# Polarfire SoC register map
Vendor: Microchip; File version: 1.0
CPU: Microchip PolarFire SoC 1.0, little endian
Registers are 32-bit, read-write, reset 0x0 unless marked. A register's access mark holds for its fields unless they carry their own. Offsets are from the block's base; [hi:lo] are bit positions.

## GEM_A_LO (part 3 of 8) — GEM_A_LO Controller
Base 0x20110000
Same registers: GEM_B_LO 0x20112000, GEM_A_HI 0x28110000, GEM_B_HI 0x28112000
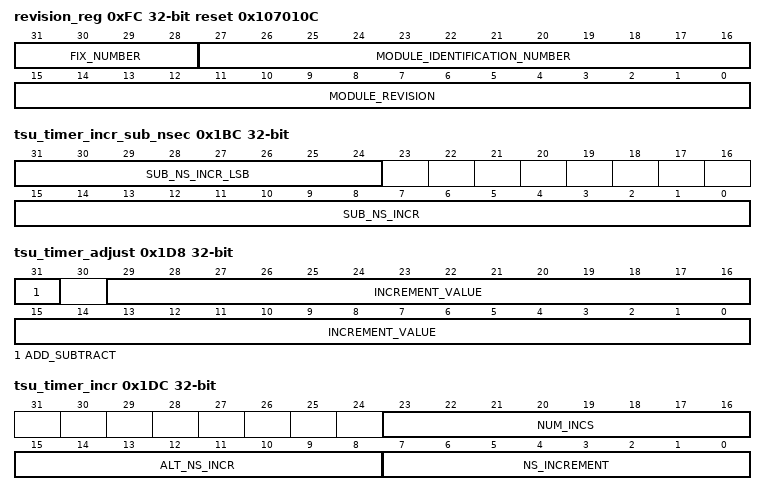
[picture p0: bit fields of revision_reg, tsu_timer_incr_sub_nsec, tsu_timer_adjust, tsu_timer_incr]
0xFC revision_reg ro reset 0x107010C — This register indicates a Cadence module identification number and module revision. The value of this register is read only as defined by 'gem_revision_reg_value
  [31:28] FIX_NUMBER — Fix number - incremented for fix releases.
  [27:16] MODULE_IDENTIFICATION_NUMBER — Module identification number - for the GEM, this value is fixed.
  [15:0] MODULE_REVISION — Module revision - fixed value specific to the revision of the design which is incremented for each non-fix release of the IP.
0x100 octets_txed_bottom ro — These registers reset to zero on a read and stick at all ones when they count to their maximum value. They should be read frequently enough to prevent loss of data. In order to reduce overall design area, the statistics registers may be optionally removed in the configuration file if they are deemed unnecessary for a particular design. The receive statistics registers are only incremented when the receive enable bit is set in the network control register. The statistics registers optionally have a snapshot capability which, when exercised, will simultaneously store and clear the current values of all the statistics registers into a snapshot register set in order to allow a consistent set of statistics to be read by the processor. The snapshot is controlled using bit 13 of the network control register. The read snapshot control indicated by bit 14 of the network control register determines whether the processor reads the snapshot registers (logic 1) or the incrementing registers (logic 0). The default GEM configuration does not support the snapshot capability. See Parameterization section under Implementation Application Notes for an explanation of how to enable this function. All the statistics registers are read only. For test purposes they may be written by setting bit 7 (Write Enable) in the network control register. Setting bit 6 (increment statistics) in the network control register causes all the statistics registers to increment by one, again for test purposes. Once a statistics register has been read, it is automatically cleared. When reading the octets transmitted and octets received registers, bits 31:0 should be read prior to bits 47:32 to ensure reliable operation. The statistics register block contains the following registers. Octets Transmitted [31:0]
  [31:0] COUNT rw — Transmitted octets in frame without errors [31:0]. The number of octets transmitted in valid frames of any type. This counter is 48-bits, and is read through two registers. This count does not include octets from automatically generated pause frames.
0x104 octets_txed_top ro — Octets Transmitted 47:32
  [15:0] COUNT rw — Transmitted octets in frame without errors [47:32]. The number of octets transmitted in valid frames of any type. This counter is 48-bits, and is read through two registers. This count does not include octets from automatically generated pause frames.
0x108 frames_txed_ok ro — Frames Transmitted
  [31:0] COUNT rw — Frames transmitted without error. A 32 bit register counting the number of frames successfully transmitted, i.e. no under run and not too many retries. Excludes pause frames.
0x10C broadcast_txed ro — Broadcast Frames Transmitted
  [31:0] COUNT rw — Broadcast frames transmitted without error. A 32 bit register counting the number of broadcast frames successfully transmitted without error, i.e. no under run and not too many retries. Excludes pause frames.
0x110 multicast_txed ro — Multicast Frames Transmitted
  [31:0] COUNT rw — Multicast frames transmitted without error. A 32 bit register counting the number of multicast frames successfully transmitted without error, i.e. no under run and not too many retries. Excludes pause frames.
0x114 pause_frames_txed ro — Pause Frames Transmitted
  [15:0] COUNT rw — Transmitted pause frames - a 16 bit register counting the number of pause frames transmitted. Only pause frames triggered by the register interface or through the external pause pins or automatically when rx_water_mark is reached are counted as pause frames. Pause frames received through the external FIFO interface are counted in the frames transmitted counter.
0x118 frames_txed_64 ro — 64 Byte Frames Transmitted
  [31:0] COUNT rw — 64 byte frames transmitted without error. A 32 bit register counting the number of 64 byte frames successfully transmitted without error, i.e. no under run and not too many retries. Excludes pause frames.
0x11C frames_txed_65 ro — 65 to 127 Byte Frames Transmitted
  [31:0] COUNT rw — 65 to127 byte frames transmitted without error. A 32 bit register counting the number of 65 to127 byte frames successfully transmitted without error, i.e. no under run and not too many retries.
0x120 frames_txed_128 ro — 128 to 255 Byte Frames Transmitted
  [31:0] COUNT rw — 128 to 255 byte frames transmitted without error. A 32 bit register counting the number of 128 to 255 byte frames successfully transmitted without error, i.e. no under run and not too many retries.
0x124 frames_txed_256 ro — 256 to 511 Byte Frames Transmitted
  [31:0] COUNT rw — 256 to 511 byte frames transmitted without error. A 32 bit register counting the number of 256 to 511 byte frames successfully transmitted without error, i.e. no under run and not too many retries.
0x128 frames_txed_512 ro — 512 to 1023 Byte Frames Transmitted
  [31:0] COUNT rw — 512 to 1023 byte frames transmitted without error. A 32 bit register counting the number of 512 to 1023 byte frames successfully transmitted without error, i.e. no under run and not too many retries.
0x12C frames_txed_1024 ro — 1024 to 1518 Byte Frames Transmitted
  [31:0] COUNT rw — 1024 to 1518 byte frames transmitted without error. A 32 bit register counting the number of 1024 to 1518 byte frames successfully transmitted without error, i.e. no under run and not too many retries.
0x130 frames_txed_1519 ro — Greater Than 1518 Byte Frames Transmitted
  [31:0] COUNT rw — Greater than 1518 byte frames transmitted without error. A 32 bit register counting the number of 1518 or above byte frames successfully transmitted without error, i.e. no under run and not too many retries.
0x134 tx_underruns ro — Transmit Under Runs
  [9:0] COUNT rw — Transmit under runs - a 10 bit register counting the number of frames not transmitted due to a transmit under run. If this register is incremented then no other statistics register is incremented.
0x138 single_collisions ro — Single Collision Frames
  [17:0] COUNT rw — Single collision frames - an 18 bit register counting the number of frames experiencing a single collision before being successfully transmitted, i.e. no under run.
0x13C multiple_collisions ro — Multiple Collision Frames
  [17:0] COUNT rw — Multiple collision frames - an 18 bit register counting the number of frames experiencing between two and fifteen collisions prior to being successfully transmitted, i.e. no under run and not too many retries.
0x140 excessive_collisions ro
  [9:0] COUNT rw — Excessive collisions - a 10 bit register counting the number of frames that failed to be transmitted because they experienced 16 collisions.
0x144 late_collisions ro
  [9:0] COUNT rw — Late collisions - a 10 bit register counting the number of late collision occurring after the slot time (512 bits) has expired. In 10/100 mode, late collisions are counted twice i.e. both as a collision and a late collision. In gigabit mode, a late collision causes the transmission to be aborted, thus the single and multi collision registers are not updated.
0x148 deferred_frames ro — Deferred Transmission Frames
  [17:0] COUNT rw — Deferred transmission frames - an 18 bit register counting the number of frames experiencing deferral due to carrier sense being active on their first attempt at transmission. Frames involved in any collision are not counted nor are frames that experienced a transmit under run.
0x14C crs_errors ro — Carrier Sense Errors
  [9:0] COUNT rw — Carrier sense errors - a 10 bit register counting the number of frames transmitted where carrier sense was not seen during transmission or where carrier sense was deasserted after being asserted in a transmit frame without collision (no under run). Only incremented in half-duplex mode. The only effect of a carrier sense error is to increment this register. The behaviour of the other statistics registers is unaffected by the detection of a carrier sense error.
0x150 octets_rxed_bottom ro — Octets Received 31:0
  [31:0] COUNT rw — Received octets in frame without errors [31:0]. The number of octets received in valid frames of any type. This counter is 48-bits and is read through two registers. This count does not include octets from pause frames, and is only incremented if the frame is successfully filtered.
0x154 octets_rxed_top ro — Octets Received 47:32
  [15:0] COUNT rw — Received octets in frame without errors [47:32]. The number of octets received in valid frames of any type. This counter is 48-bits and is read through two registers. This count does not include octets from pause frames, and is only incremented if the frame is successfully filtered.
0x158 frames_rxed_ok ro — Frames Received
  [31:0] COUNT rw — Frames received without error. A 32 bit register counting the number of frames successfully received. Excludes pause frames, and is only incremented if the frame is successfully filtered.
0x15C broadcast_rxed ro — Broadcast Frames Received
  [31:0] COUNT rw — Broadcast frames received without error. A 32 bit register counting the number of broadcast frames successfully received without error. Excludes pause frames, and is only incremented if the frame is successfully filtered.
0x160 multicast_rxed ro — Multicast Frames Received
  [31:0] COUNT rw — Multicast frames received without error. A 32 bit register counting the number of multicast frames successfully received without error. Excludes pause frames, and is only incremented if the frame is successfully filtered.
0x164 pause_frames_rxed ro — Pause Frames Received
  [15:0] COUNT rw — Received pause frames - a 16 bit register counting the number of pause frames received without error.
0x168 frames_rxed_64 ro — 64 Byte Frames Received
  [31:0] COUNT rw — 64 byte frames received without error. A 32 bit register counting the number of 64 byte frames successfully received without error. Excludes pause frames, and is only incremented if the frame is successfully filtered.
0x16C frames_rxed_65 ro — 65 to 127 Byte Frames Received
  [31:0] COUNT rw — 65 to 127 byte frames received without error. A 32 bit register counting the number of 65 to 127 byte frames successfully received without error. Excludes pause frames, and is only incremented if the frame is successfully filtered.
0x170 frames_rxed_128 ro — 128 to 255 Byte Frames Received
  [31:0] COUNT rw — 128 to 255 byte frames received without error. A 32 bit register counting the number of 128 to 255 byte frames successfully received without error. Excludes pause frames, and is only incremented if the frame is successfully filtered.
0x174 frames_rxed_256 ro — 256 to 511 Byte Frames Received
  [31:0] COUNT rw — 256 to 511 byte frames received without error. A 32 bit register counting the number of 256 to 511 byte frames successfully transmitted without error. Excludes pause frames, and is only incremented if the frame is successfully filtered.
0x178 frames_rxed_512 ro — 512 to 1023 Byte Frames Received
  [31:0] COUNT rw — 512 to 1023 byte frames received without error. A 32 bit register counting the number of 512 to 1023 byte frames successfully received without error. Excludes pause frames, and is only incremented if the frame is successfully filtered.
0x17C frames_rxed_1024 ro — 1024 to 1518 Byte Frames Received
  [31:0] COUNT rw — 1024 to 1518 byte frames received without error. A 32 bit register counting the number of 1024 to 1518 byte frames successfully received without error. Excludes pause frames, and is only incremented if the frame is successfully filtered.
0x180 frames_rxed_1519 ro — 1519 to maximum Byte Frames Received
  [31:0] COUNT rw — 1519 to maximum byte frames received without error. A 32 bit register counting the number of 1519 byte or above frames successfully received without error. Maximum frame size is determined by the network configuration register bit 8 (1536 maximum frame size) or bit 3 (jumbo frame size). Excludes pause frames, and is only incremented if the frame is successfully filtered.
0x184 undersize_frames ro — Undersized Frames Received
  [9:0] COUNT rw — Undersize frames received - a 10 bit register counting the number of frames received less than 64 bytes in length (10/100 mode or gigabit mode, full duplex) that do not have either a CRC error or an alignment error. In gigabit mode, half-duplex, this register counts either frames not conforming to the minimum slot time of 512 bytes or frames not conforming to the minimum frame size once bursting is active.
0x188 excessive_rx_length ro — Oversize Frames Received
  [9:0] COUNT rw — Oversize frames received - a 10 bit register counting the number of frames received exceeding 1518 bytes (1536 bytes if bit 8 is set in network configuration register, 10,240 bytes if bit 3 is set in the network configuration register) in length but do not have either a CRC error, an alignment error nor a receive symbol error.
0x18C rx_jabbers ro — Jabbers Received
  [9:0] COUNT rw — Jabbers received - a 10 bit register counting the number of frames received exceeding 1518 bytes (1536 if bit 8 set in network configuration register, 10,240 bytes if bit 3 is set in the network configuration register) in length and have either a CRC error, an alignment error or a receive symbol error.
0x190 fcs_errors ro — Frame Check Sequence Errors
  [9:0] COUNT rw — Frame check sequence errors - a 10 bit register counting frames that are an integral number of bytes, have bad CRC and are between 64 and 1518 bytes in length (1536 if bit 8 set in network configuration register, 10,240 bytes if bit 3 is set in the network configuration register). This register is also incremented if a symbol error is detected and the frame is of valid length and has an integral number of bytes. This register is incremented for a frame with bad FCS, regardless of whether it is copied to memory due to ignore FCS mode being enabled in bit 26 of the network configuration register.
0x194 rx_length_errors ro — Length Field Frame Errors
  [9:0] COUNT rw — Length field frame errors - this 10-bit register counts the number of frames received that have a measured length shorter than that extracted from the length field (bytes 13 and 14). This condition is only counted if the value of the length field is less than 0x0600, the frame is not of excessive length and checking is enabled through bit 16 of the network configuration register.
0x198 rx_symbol_errors ro — Receive Symbol Errors
  [9:0] COUNT rw — Receive symbol errors - a 10-bit register counting the number of frames that had rx_er asserted during reception. For 10/100 mode symbol errors are counted regardless of frame length checks. For gigabit mode the frame must satisfy slot time requirements in order to count a symbol error. Additionally, in gigabit half-duplex mode, carrier extension errors are also recorded. Receive symbol errors will also be counted as an FCS or alignment error if the frame is between 64 and 1518 bytes (1536 bytes if bit 8 is set in the network configuration register, 10240 bytes if bit 3 is set in the network configuration register). If the frame is larger it will be recorded as a jabber error.
0x19C alignment_errors ro
  [9:0] COUNT rw — Alignment errors - a 10 bit register counting frames that are not an integral number of bytes long and have bad CRC when their length is truncated to an integral number of bytes and are between 64 and 1518 bytes in length (1536 if bit 8 set in network configuration register, 10,240 bytes if bit 3 is set in the network configuration register). This register is also incremented if a symbol error is detected and the frame is of valid length and does not have an integral number of bytes.
0x1A0 rx_resource_errors ro — Receive Resource Errors
  [17:0] COUNT rw — Receive resource errors - an 18 bit register counting the number of times a receive buffer descriptor was read with its used bit set. This can be used as a means of checking the efficiency of the software in processing and releasing receive buffers. In an ideally configured system, this counter would not increase.
0x1A4 rx_overruns ro — Receive Overruns
  [9:0] COUNT rw — Receive overruns - a 10 bit register counting the number of frames that are address recognized but were not copied to memory due to a receive overrun.
0x1A8 rx_ip_ck_errors ro — IP Header Checksum Errors
  [7:0] COUNT rw — IP header checksum errors - an 8-bit register counting the number of frames discarded due to an incorrect IP header checksum, but are between 64 and 1518 bytes (1536 bytes if bit 8 is set in the network configuration register or 10240 bytes if bit 3 is in the network configuration register) and do not have a CRC error, an alignment error, nor a symbol error.
0x1AC rx_tcp_ck_errors ro — TCP Checksum Errors
  [7:0] COUNT rw — TCP checksum errors - an 8-bit register counting the number of frames discarded due to an incorrect TCP checksum, but are between 64 and 1518 bytes (1536 bytes if bit 8 is set in the network configuration register or 10240 bytes if bit 3 is in the network configuration register) and do not have a CRC error, an alignment error, nor a symbol error.
0x1B0 rx_udp_ck_errors ro — UDP Checksum Errors
  [7:0] COUNT rw — UDP checksum errors - an 8-bit register counting the number of frames discarded due to an incorrect UDP checksum, but are between 64 and 1518 bytes (1536 bytes if bit 8 is set in the network configuration register or 10240 bytes if bit 3 is in the network configuration register) and do not have a CRC error, an alignment error, nor a symbol error.
0x1B4 auto_flushed_pkts ro — Receive DMA Flushed Packets
  [15:0] COUNT rw — Flushed RX packets counter. A 16 bit register counting the number of frames that have been flushed from the receive SRAM based packet buffer due to one of the following reasons:, :1. When either partial store and forward mode, bit 24 of the DMA configuration register, or the drop_on_resource_err mode of the traffic policing feature is active, and a packet is received while there is no AMBA (AHB/AXI) resource (no free descriptors for the DUT to use)., :2. When partial store and forward mode is enabled and an AMBA (AHB/AXI) error is encountered while writing the packet data to external memory., :3. When bit 18 of the network control register (software action to flush a packet from the head of the PBUF queue) is pulsed and the GEM DMA is not currently busy., :4. When a frame is dropped due to the policing actions defined in the rx_qX_flush registers located at 0x0b00-0x0b3c.
0x1BC tsu_timer_incr_sub_nsec — 1588 Timer Increment Register sub nsec. From release 1p08f1 onwards this register must be written before the tsu_timer_incr register and the value written will not take effect until the tsu_timer_incr register is written to.
  [31:24] SUB_NS_INCR_LSB — These are the least significant bits [7:0] of the sub-ns value by which the 1588 timer will be incremented each clock cycle.
  [15:0] SUB_NS_INCR — These are the most significant bits [23:8] of the sub-ns value by which the 1588 timer will be incremented each clock cycle. 24 bits of sub nanosecond precision gives resolution of approximately 5.86E-17 seconds (16 bits gives 15.2 femtoseconds).
0x1C0 tsu_timer_msb_sec — 1588 Timer Seconds Register 47:32
  [15:0] TIMER — TSU timer value (s). Most significant 16 bits of seconds timer count. The register is writeable. The 48-bit counter increments by one when the 1588 nanoseconds counter counts to one second. It may also be incremented or decremented when the timer adjust register is written (if decremented from zero the 48-bit combined count would roll back to 0xFFFFFFFFFFFF). Note: The value of this register is used only when the lower 32 bit register is written to. This is to ensure a single update of the 48 bit seconds value
0x1C4 tsu_strobe_msb_sec ro — 1588 Timer Sync Strobe Seconds Register 47:32
  [15:0] STROBE — 1588 Timer Sync Strobe Seconds. The most significant 16-bit value of the Timer Seconds register captured when gem_tsu_ms and gem_tsu_inc_ctrl are zero.
0x1C8 tsu_strobe_sec ro — 1588 Timer Sync Strobe Seconds Register 31:0
  [31:0] STROBE — 1588 Timer Sync Strobe Seconds. The lowest significant 32-bit value of the Timer Seconds register captured when gem_tsu_ms and gem_tsu_inc_ctrl are zero.
0x1CC tsu_strobe_nsec ro — 1588 Timer Sync Strobe Nanoseconds Register
  [29:0] STROBE — 1588 Timer Sync Strobe Nanoseconds. The value of the Timer Nanoseconds register captured when gem_tsu_ms and gem_tsu_inc_ctrl are zero.
0x1D0 tsu_timer_sec — 1588 Timer Seconds Register 31:0
  [31:0] TIMER — 1588 Timer Seconds Register. TSU timer value (s). Least significant 32 bits of seconds timer count. This register is writeable. The 48-bit counter increments by one when the 1588 nanoseconds counter counts to one second. It may also be incremented or decremented when the timer adjust register is written (if decremented from zero the 48-bit combined count would roll back to 0xFFFFFFFFFFFF).
0x1D4 tsu_timer_nsec — 1588 Timer Nanoseconds Register
  [29:0] TIMER — Timer count in nanoseconds. This register is writeable. It can also be adjusted by writes to the 1588 timer adjust register. It increments by the value of the 1588 timer increment register each clock cycle (if this register is close to zero and a write to the timer adjust register causes a decrement the seconds register will be decremented if necessary and the nanoseconds register will roll back to 9999999xx (decimal)).
0x1D8 tsu_timer_adjust — This register is used to adjust the value of the timer in the TSU. It allows an integral number of nanoseconds to be added or subtracted from the timer in a one-off operation. This register returns all zeroes when read.
  [31] ADD_SUBTRACT — Write as one to subtract from the 1588 timer. Write as zero to add to it.
  [29:0] INCREMENT_VALUE — Timer increment value. The number of nanoseconds to increment or decrement the 1588 timer nanoseconds register. If necessary the 1588 seconds register will be incremented or decremented.
0x1DC tsu_timer_incr — 1588 Timer Increment Register. From release 1p08f1 onwards this register must be written after the tsu_timer_incr_sub_ns register and the write operation will cause the value written to the tsu_timer_incr_sub_ns register to take effect.
  [23:16] NUM_INCS — Number of incs before alt inc. The number of increments after which the alternative increment is used.
  [15:8] ALT_NS_INCR — Alternative nanoseconds count. Alternative count of nanoseconds by which the 1588 timer nanoseconds register will be incremented each clock cycle.
  [7:0] NS_INCREMENT — A count of nanoseconds by which the 1588 timer nanoseconds register will be incremented each clock cycle. These are the most significant 8 bits of the 32 bit timer_increment counter. The tsu_timer_incr_sub_nsec register holds the least significant 24 bits of the increment.
0x1E0 tsu_ptp_tx_sec ro — PTP Event Frame Transmitted Seconds Register 31:0
  [31:0] TIMER — PTP Event Frame Transmitted Seconds. The register is updated with the value that the 1588 timer seconds register held when the SFD of a PTP transmit primary event crosses the MII interface. The actual update occurs when the GEM recognizes the frame as a PTP sync or delay_req frame. An interrupt is issued when the register is updated.
0x1E4 tsu_ptp_tx_nsec ro — PTP Event Frame Transmitted Nanoseconds Register
  [29:0] TIMER — PTP Event Frame Transmitted Nanoseconds. The register is updated with the value that the 1588 timer nanoseconds register held when the SFD of a PTP transmit primary event crosses the MII interface. The actual update occurs when the GEM recognizes the frame as a PTP sync or delay_req frame. An interrupt is issued when the register is updated.
0x1E8 tsu_ptp_rx_sec ro — PTP Event Frame Received Seconds Register 31:0
  [31:0] TIMER — PTP Event Frame Received Seconds. The register is updated with the value that the 1588 timer seconds register held when the SFD of a PTP receive primary event crosses the MII interface. The actual update occurs when the GEM recognizes the frame as a PTP sync or delay_req frame. An interrupt is issued when the register is updated.
0x1EC tsu_ptp_rx_nsec ro — PTP Event Frame Received Nanoseconds Register
  [29:0] TIMER — PTP Event Frame Received Nanoseconds. The register is updated with the value that the 1588 timer nanoseconds register held when the SFD of a PTP receive primary event crosses the MII interface. The actual update occurs when the GEM recognizes the frame as a PTP sync or delay_req frame. An interrupt is issued when the register is updated.
0x1F0 tsu_peer_tx_sec ro — PTP Peer Event Frame Transmitted Seconds Register 31:0
  [31:0] TIMER — PTP Peer Event Frame Received Seconds. The register is updated with the value that the 1588 timer seconds register held when the SFD of a PTP transmit peer event crosses the MII interface. The actual update occurs when the GEM recognizes the frame as a PTP pdelay_req or pdelay_resp frame. An interrupt is issued when the register is updated.
0x1F4 tsu_peer_tx_nsec ro — PTP Peer Event Frame Transmitted Nanoseconds Register
  [29:0] TIMER — PTP Peer Event Frame Transmitted Nanoseconds. The register is updated with the value that the 1588 timer nanoseconds register held when the SFD of a PTP transmit peer event crosses the MII interface. The actual update occurs when the GEM recognizes the frame as a PTP pdelay_req or pdelay_resp frame. An interrupt is issued when the register is updated.
0x1F8 tsu_peer_rx_sec ro — PTP Peer Event Frame Received Seconds Register 31:0
  [31:0] TIMER — PTP Peer Event Frame Received Seconds. The register is updated with the value that the 1588 timer seconds register held when the SFD of a PTP receive peer event crosses the MII interface. The actual update occurs when the GEM recognizes the frame as a PTP pdelay_req or pdelay_resp frame. An interrupt is issued when the register is updated.
0x1FC tsu_peer_rx_nsec ro — PTP Peer Event Frame Received Nanoseconds Register
  [29:0] TIMER — PTP Peer Event Frame Received Nanoseconds. The register is updated with the value that the 1588 timer nanoseconds register held when the SFD of a PTP receive peer event crosses the MII interface. The actual update occurs when the GEM recognizes the frame as a PTP pdelay_req or pdelay_resp frame. An interrupt is issued when the register is updated.
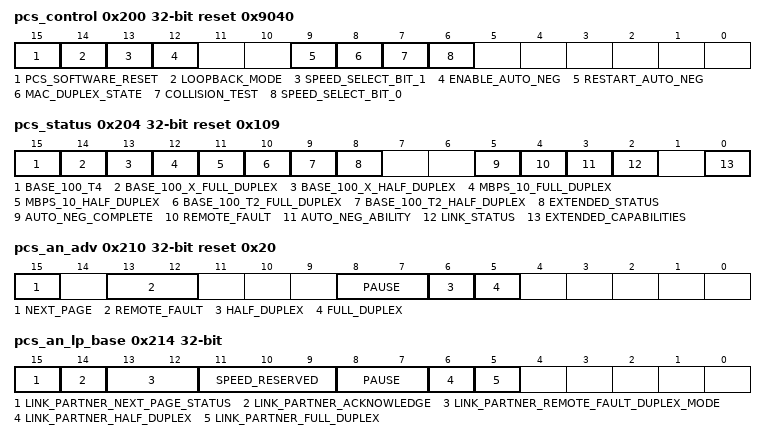
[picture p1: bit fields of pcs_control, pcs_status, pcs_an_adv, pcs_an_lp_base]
0x200 pcs_control reset 0x9040 — Note: All PCS registers are defined in the IEEE 802.3 Standard. PCS Control Register. This register provides the main control functions with respect to the PCS.
  [15] PCS_SOFTWARE_RESET — PCS software reset - written by software to force the hardware logic into a reset state. This bit is self-clearing. When reading this bit, logic 1 is returned until both the soft reset has completed and the PCS is enabled through the PCS select bit of the network configuration register. Writing logic 0 has no effect.
  [14] LOOPBACK_MODE — Loopback mode - the ewrap output pin of the GEM reflects this control bit, and can be used to select loopback mode in the PHY transceiver. 0: Loopback mode disabled. 1: Loopback mode enabled.
  [13] SPEED_SELECT_BIT_1 ro — Speed select bit 1 - combined with speed select [0] to indicate the speed of operation of the PCS. As the GEM PCS is only intended to operate at 1000 Mbps, this bit is hardwired to logic 0.
  [12] ENABLE_AUTO_NEG — Enable auto-negotiation - when set active high, auto-negotiation operation is enabled.
  [9] RESTART_AUTO_NEG — Restart auto-negotiation - when set active high, the hardware restarts auto-negotiation. This bit is self-clearing, but once set shall remain in this state until auto-negotiation has restarted. Writing logic 0 has no effect.
  [8] MAC_DUPLEX_STATE ro — MAC Duplex state. This returns the value of the MAC's duplex state as indicated in bit 1 of the MAC's network configuration register.
  [7] COLLISION_TEST — Collision test - when set active high, the PCS generates collisions on transmit. This bit should only be set for test purposes.
  [6] SPEED_SELECT_BIT_0 ro — Speed select bit 0 - combined with speed select [1] to indicate the speed of operation of the PCS. As the GEM PCS is only intended to operate at 1000 Mbps, this bit is hardwired to logic 1.
0x204 pcs_status ro reset 0x109 — This register indicates general status information concerning the PCS.
  [15] BASE_100_T4 — 100 BASE-T4 - the GEM PCS does not support 100 BASE-T4. This bit is hardwired to logic 0.
  [14] BASE_100_X_FULL_DUPLEX — 100 BASE-X full duplex - the GEM PCS does not support 100 BASE-X. This bit is hardwired to logic 0.
  [13] BASE_100_X_HALF_DUPLEX — 100 BASE-X half-duplex - the GEM PCS does not support 100 BASE-X. This bit is hardwired to logic 0.
  [12] MBPS_10_FULL_DUPLEX — 10 Mbps full duplex - the GEM PCS does not support this mode. This bit is hardwired to logic 0.
  [11] MBPS_10_HALF_DUPLEX — 10 Mbps half-duplex - the GEM PCS does not support this mode. This bit is hardwired to logic 0.
  [10] BASE_100_T2_FULL_DUPLEX — 100 BASE-T2 full duplex - the GEM PCS does not support 100 BASE-T2. This bit is hardwired to logic 0.
  [9] BASE_100_T2_HALF_DUPLEX — 100 BASE-T2 half-duplex - the GEM PCS does not support 100 BASE-T2. This bit is hardwired to logic 0.
  [8] EXTENDED_STATUS — Extended status - when set active high, indicates extended status information is present in the PCS auto-negotiation extended status register. This bit is hardwired to logic 1.
  [5] AUTO_NEG_COMPLETE — Auto-negotiation complete - set active high by the PCS hardware to indicate auto-negotiation has completed.
  [4] REMOTE_FAULT — Remote fault - set active high if the link partner remote fault bits in the PCS auto-negotiation link partner ability register, indicates an error. Resets low when read.
  [3] AUTO_NEG_ABILITY — Auto-negotiation ability - this bit indicates whether the PCS has auto-negotiation ability and reflects the value of the auto-negotiation enable bit in the PCS control register. 0: PCS is not able to perform auto-negotiation. 1: PCS is able to perform auto-negotiation.
  [2] LINK_STATUS — Link status - indicates the status of the physical connection to the link partner. When set to logic 1 the link is up, and when set to logic 0, the link is down. If auto-negotiation is disabled this returns the synchronisation status. Held at logic 0 if the link goes down until this bit is read.
  [0] EXTENDED_CAPABILITIES — Extended register capabilities - when set active high, indicates the PCS supports extended register capabilities. This bit is hardwired to logic 1.
0x208 pcs_phy_top_id ro reset 0x107 — The value of this register indicates the upper 16-bits of the PHY's identification code. This is a read-only register with a value defined by 'gem_phy_id_top
  [15:0] ID_CODE — Upper 16-bits of the PHY identification code, corresponding to the fixed identification for the GEM IP.
0x20C pcs_phy_bot_id ro reset 0x10C — The value of this register indicates the lower 16-bits of the PHY's identification code. This is a read-only register with a value defined by 'gem_phy_id_bot
  [15:0] ID_CODE — Lower 16-bits of the PHY identification code, corresponding to the revision of the GEM IP, which is incremented after each release of the IP.
0x210 pcs_an_adv reset 0x20 — The value of this register is used to transmit the base page of the GEM PCS advertised capabilities as long as SGMII mode is not enabled. If SGMII mode is enabled by setting bit 27 in the network configuration register then this register becomes read only with a fixed value of 0x00000001. (SGMII specifies that the transmit configuration information sent from the MAC to the PHY is fixed with bit 14 set to 1 to indicate acknowledge, bit 0 set to 1 to indicate SGMII and all other bits set to 0.)
  [15] NEXT_PAGE — Next page. When set active high, this bit is used during auto-negotiation to indicate to the link partner that the PCS requires exchanging next pages.
  [13:12] REMOTE_FAULT — Remote fault [1:0] - indicates and classifies a remote fault condition to the link partner:, :00: No error, Link OK, :01: Link Failure. , :10: Off line. , :11: Auto-negotiation error.
  [8:7] PAUSE — Pause[1:0] - used to provide a pause capability mechanism as follows:, :00: No pause. , :01: Symmetric pause. , :10: Asymmetric pause toward link partner. , :11: Both symmetric pause and asymmetric pause toward link device.
  [6] HALF_DUPLEX — half-duplex - this bit defines to the link partner whether the GEM is capable of supporting half-duplex operation., :0: The GEM cannot support half-duplex. , :1: The GEM can support half-duplex.
  [5] FULL_DUPLEX — Full duplex - this bit defines to the link partner whether the GEM is capable of supporting full duplex operation. , :0: The GEM cannot support full duplex. , :1: The GEM can support full duplex.
0x214 pcs_an_lp_base ro — When SGMII mode is not enabled, the value of this register contains the link partner's base page received information. This register is updated in the ABILITY_DETECT state of the PCS auto-negotiation state machine so bit 14 will only be set if the link partner is sending acknowledge while the PCS in this state. The register is not updated in the ACK_DETECT state. For SGMII mode, the contents of this register change to the one defined in the SGMII standard. The value of this register contains the link partner's base page received information. In this case the link partner is the PHY connected by the SGMII.
  [15] LINK_PARTNER_NEXT_PAGE_STATUS — The contents of this register change depending on SGMII or non SGMII mode., :, :non SGMII Mode:, :Link partner next page - when set active high, this bit indicates the link partner's intention to exchange next pages., :, :SGMII Mode: , :Link Status., :0 : Link Down., :1 : Link Up.
  [14] LINK_PARTNER_ACKNOWLEDGE — Link partner acknowledge - indicates the link partner has successfully received the transmitted base page
  [13:12] LINK_PARTNER_REMOTE_FAULT_DUPLEX_MODE — The contents of this register change depending on SGMII or non SGMII mode., :, :non SGMII Mode:, :Link partner remote fault [1:0] - indicates and classifies a remote fault condition has been detected by the link partner as follows:, :00: No error, Link OK, :01: Link Failure., :10: Off line. , :11: Auto-negotiation error., :, :SGMII Mode:, :Bit 13: Reserved. read as 0., :Bit 12 : 0 : half-duplex. 1: Full Duplex.
  [11:9] SPEED_RESERVED — The contents of this register change depending on SGMII or non SGMII mode., :, :non SGMII Mode:, :Reserved. Set to zero., :, :SGMII Mode :, :Bits 11:10 : Speed : , :11 : Reserved, :10 : 1000 Mbps, :01 : 100Mbps, :00 : 10 Mbps, :Bit 9 : Reserved. read as 0.
  [8:7] PAUSE — The contents of this register change depending on SGMII or non SGMII mode., :, :non SGMII Mode:, :Pause[1:0] - provides the link partner's pause frame capability as follows:, :00: No pause. , :01: Symmetric pause. , :10: Asymmetric pause toward link partner. , :11: Both symmetric pause and asymmetric pause toward link device., :, :SGMII Mode:, :Reserved. read as 0.
  [6] LINK_PARTNER_HALF_DUPLEX — The contents of this register change depending on SGMII or non SGMII mode., :, :non SGMII Mode:, :Link partner half-duplex - this bit indicates whether the link partner is capable of supporting half-duplex operation. , :0: The link partner cannot support half-duplex. , :1: The link partner can support half-duplex., :, :SGMII Mode: , :Reserved. read as 0.
  [5] LINK_PARTNER_FULL_DUPLEX — The contents of this register change depending on SGMII or non SGMII mode., :, :non SGMII Mode:, :Link partner full duplex - this bit indicates whether the link partner is capable of supporting full duplex operation. , :0: The link partner cannot support full duplex. , :1: The link partner can support full duplex., :, :SGMII Mode: , :Reserved. read as 0.
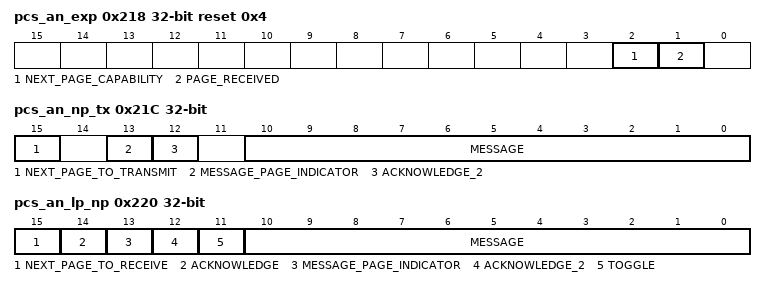
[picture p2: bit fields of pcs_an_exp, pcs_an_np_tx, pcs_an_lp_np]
0x218 pcs_an_exp ro reset 0x4 — This register contains auto-negotiation next page ability and page received information.
  [2] NEXT_PAGE_CAPABILITY — Next page capability - hard wired to logic 1 to indicate that the GEM PCS supports next page operation.
  [1] PAGE_RECEIVED — Page received - this bit is set active high when a new page has been received from the link partner. It is cleared when the link partner next page register has been read.
0x21C pcs_an_np_tx — The value of this register is used to transmit the next page information for the GEM PCS. For next page exchange to work this register must be written within 10 ms of receiving a new page from the link partner. If the link partner is requesting next pages and the GEM has none or no more to send then this register should be written with the null message (0x2001). The value 0x0000 must not be written to this register.
  [15] NEXT_PAGE_TO_TRANSMIT — Next page to transmit - this bit indicates whether this is the last next page to be transmitted:0: Last page. 1: Additional page(s) to follow.
  [13] MESSAGE_PAGE_INDICATOR — Message page indicator - this bit identifies the message. 0: Unformatted page. 1: Message page.
  [12] ACKNOWLEDGE_2 — Acknowledge 2 - when set active high, indicates that the GEM PCS has the ability to comply with the last received message.
  [10:0] MESSAGE — Message - contains data as defined by the message page indicator bit.
0x220 pcs_an_lp_np ro — This value of this register contains the next page received information from the link partner.
  [15] NEXT_PAGE_TO_RECEIVE — Next page to receive - this bit indicates whether this is the last page to be received in the sequence by the GEM PCS:, :0: Last page. , :1: Additional page(s) to follow.
  [14] ACKNOWLEDGE — Acknowledge - this bit indicates whether as part of the next page function, the link partner has successfully received the last message transmitted.
  [13] MESSAGE_PAGE_INDICATOR — Message page indicator - this bit identifies the message. , :0: Unformatted page. , :1: Message page.
  [12] ACKNOWLEDGE_2 — Acknowledge 2 - set active high by the link partner to indicate when it has the ability to comply with the last message received.
  [11] TOGGLE — Toggle - this bit toggles with every received page.
  [10:0] MESSAGE — Message - contains data as defined by the message page indicator bit.
